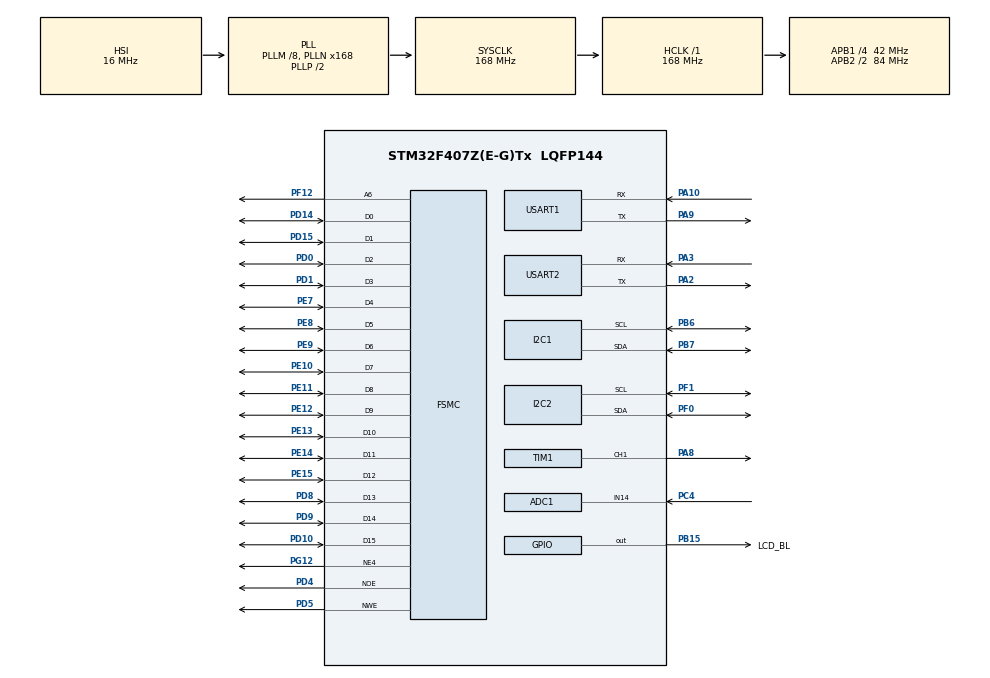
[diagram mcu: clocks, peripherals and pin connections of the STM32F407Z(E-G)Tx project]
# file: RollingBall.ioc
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ADC1.Channel-2\#ChannelRegularConversion=ADC_CHANNEL_14
ADC1.ContinuousConvMode=ENABLE
ADC1.NbrOfConversionFlag=1
ADC1.Rank-2\#ChannelRegularConversion=1
ADC1.SamplingTime-2\#ChannelRegularConversion=ADC_SAMPLETIME_3CYCLES
ADC1.master=1
I2C1.I2C_Mode=I2C_Fast
Mcu.Family=STM32F4
Mcu.Name=STM32F407Z(E-G)Tx
Mcu.Package=LQFP144
NVIC.ADC_IRQn=true\:0\:0\:false\:true\:true\:1\:true\:true
NVIC.PriorityGroup=NVIC_PRIORITYGROUP_4
NVIC.TIM2_IRQn=true\:15\:0\:false\:false\:true\:false\:true
NVIC.TimeBase=TIM2_IRQn
NVIC.TimeBaseIP=TIM2
NVIC.USART1_IRQn=true\:0\:0\:false\:true\:true\:2\:true\:true
NVIC.USART2_IRQn=true\:0\:0\:false\:true\:true\:3\:true\:true
PA10.Mode=Asynchronous
PA10.Signal=USART1_RX
PA13.Mode=JTAG_5_pins
PA13.Signal=SYS_JTMS-SWDIO
PA14.Mode=JTAG_5_pins
PA14.Signal=SYS_JTCK-SWCLK
PA15.Mode=JTAG_5_pins
PA15.Signal=SYS_JTDI
PA2.Mode=Asynchronous
PA2.Signal=USART2_TX
PA3.Mode=Asynchronous
PA3.Signal=USART2_RX
PA8.Signal=S_TIM1_CH1
PA9.Mode=Asynchronous
PA9.Signal=USART1_TX
PB15.GPIO_Label=LCD_BL
PB15.Signal=GPIO_Output
PB3.Mode=JTAG_5_pins
PB3.Signal=SYS_JTDO-SWO
PB4.Mode=JTAG_5_pins
PB4.Signal=SYS_JTRST
PB6.GPIO_Pu=GPIO_PULLUP
PB6.Mode=I2C
PB6.Signal=I2C1_SCL
PB7.GPIO_Pu=GPIO_PULLUP
PB7.Mode=I2C
PB7.Signal=I2C1_SDA
PC14-OSC32_IN.Mode=LSE-External-Oscillator
PC14-OSC32_IN.Signal=RCC_OSC32_IN
PC15-OSC32_OUT.Mode=LSE-External-Oscillator
PC15-OSC32_OUT.Signal=RCC_OSC32_OUT
PC4.Signal=ADCx_IN14
PD0.Signal=FSMC_D2_DA2
PD1.Signal=FSMC_D3_DA3
PD10.Signal=FSMC_D15_DA15
PD14.Signal=FSMC_D0_DA0
PD15.Signal=FSMC_D1_DA1
PD4.Signal=FSMC_NOE
PD5.Signal=FSMC_NWE
PD8.Signal=FSMC_D13_DA13
PD9.Signal=FSMC_D14_DA14
PE10.Signal=FSMC_D7_DA7
PE11.Signal=FSMC_D8_DA8
PE12.Signal=FSMC_D9_DA9
PE13.Signal=FSMC_D10_DA10
PE14.Signal=FSMC_D11_DA11
PE15.Signal=FSMC_D12_DA12
PE7.Signal=FSMC_D4_DA4
PE8.Signal=FSMC_D5_DA5
PE9.Signal=FSMC_D6_DA6
PF0.Mode=I2C
PF0.Signal=I2C2_SDA
PF1.Mode=I2C
PF1.Signal=I2C2_SCL
PF12.Signal=FSMC_A6
PG12.Mode=NorPsramChipSelect4_1
PG12.Signal=FSMC_NE4
PH0-OSC_IN.Mode=HSE-External-Oscillator
PH0-OSC_IN.Signal=RCC_OSC_IN
PH1-OSC_OUT.Mode=HSE-External-Oscillator
PH1-OSC_OUT.Signal=RCC_OSC_OUT
ProjectManager.HeapSize=0x200
ProjectManager.StackSize=0x400
ProjectManager.TargetToolchain=STM32CubeIDE
RCC.48MHZClocksFreq_Value=84000000
RCC.AHBFreq_Value=168000000
RCC.APB1CLKDivider=RCC_HCLK_DIV4
RCC.APB1Freq_Value=42000000
RCC.APB1TimFreq_Value=84000000
RCC.APB2CLKDivider=RCC_HCLK_DIV2
RCC.APB2Freq_Value=84000000
RCC.APB2TimFreq_Value=168000000
RCC.CortexFreq_Value=168000000
RCC.HCLKFreq_Value=168000000
RCC.HSE_VALUE=8000000
RCC.HSI_VALUE=16000000
RCC.PLLM=8
RCC.PLLN=168
RCC.SYSCLKFreq_VALUE=168000000
RCC.SYSCLKSource=RCC_SYSCLKSOURCE_PLLCLK
RCC.VCOOutputFreq_Value=336000000
SH.ADCx_IN14.0=ADC1_IN14,IN14
SH.FSMC_A6.0=FSMC_A6,A6_1
SH.FSMC_D0_DA0.0=FSMC_D0,16b-d1
SH.FSMC_D10_DA10.0=FSMC_D10,16b-d1
SH.FSMC_D11_DA11.0=FSMC_D11,16b-d1
SH.FSMC_D12_DA12.0=FSMC_D12,16b-d1
SH.FSMC_D13_DA13.0=FSMC_D13,16b-d1
SH.FSMC_D14_DA14.0=FSMC_D14,16b-d1
SH.FSMC_D15_DA15.0=FSMC_D15,16b-d1
SH.FSMC_D1_DA1.0=FSMC_D1,16b-d1
SH.FSMC_D2_DA2.0=FSMC_D2,16b-d1
SH.FSMC_D3_DA3.0=FSMC_D3,16b-d1
SH.FSMC_D4_DA4.0=FSMC_D4,16b-d1
SH.FSMC_D5_DA5.0=FSMC_D5,16b-d1
SH.FSMC_D6_DA6.0=FSMC_D6,16b-d1
SH.FSMC_D7_DA7.0=FSMC_D7,16b-d1
SH.FSMC_D8_DA8.0=FSMC_D8,16b-d1
SH.FSMC_D9_DA9.0=FSMC_D9,16b-d1
SH.FSMC_NOE.0=FSMC_NOE,Lcd1
SH.FSMC_NWE.0=FSMC_NWE,Lcd1
SH.S_TIM1_CH1.0=TIM1_CH1,PWM Generation1 CH1
TIM1.Channel-PWM\ Generation1\ CH1=TIM_CHANNEL_1
TIM1.Period=19999
TIM1.Prescaler=167
USART1.VirtualMode=VM_ASYNC
USART2.VirtualMode=VM_ASYNC
VP_SYS_VS_tim2.Mode=TIM2
VP_TIM1_VS_ClockSourceINT.Mode=Internal
board=custom

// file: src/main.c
/* USER CODE BEGIN Header */
/**
  ******************************************************************************
  * @file           : main.c
  * @brief          : Main program body
  ******************************************************************************
  * @attention
  *
  * <h2><center>&copy; Copyright (c) 2021 STMicroelectronics.
  * All rights reserved.</center></h2>
  *
  * This software component is licensed by ST under BSD 3-Clause license,
  * the "License"; You may not use this file except in compliance with the
  * License. You may obtain a copy of the License at:
  *                        opensource.org/licenses/BSD-3-Clause
  *
  ******************************************************************************
  */
/* USER CODE END Header */
#include "main.h"
#include "adc.h"
#include "i2c.h"
#include "tim.h"
#include "usart.h"
#include "gpio.h"
#include "fsmc.h"

/* USER CODE BEGIN Includes */
#include "RollingBall.h"
/* USER CODE END Includes */

void SystemClock_Config(void);
static void MX_NVIC_Init(void);

int main(void)
{

  /* MCU Configuration--------------------------------------------------------*/

  /* Reset of all peripherals, Initializes the Flash interface and the Systick. */
  HAL_Init();

  /* Configure the system clock */
  SystemClock_Config();

  /* Initialize all configured peripherals */
  MX_GPIO_Init();
  MX_TIM1_Init();
  MX_USART1_UART_Init();
  MX_USART2_UART_Init();
  MX_FSMC_Init();
  MX_I2C1_Init();
  MX_ADC1_Init();
  MX_I2C2_Init();

  /* Initialize interrupts */
  MX_NVIC_Init();
  /* USER CODE BEGIN 2 */
  rolling_ball_init();
  /* USER CODE END 2 */

  /* Infinite loop */
  while (1)
  {

    /* USER CODE BEGIN 3 */
    updateHandler();
  }
  /* USER CODE END 3 */
}

void SystemClock_Config(void)
{
  RCC_OscInitTypeDef RCC_OscInitStruct = {0};
  RCC_ClkInitTypeDef RCC_ClkInitStruct = {0};

  /** Configure the main internal regulator output voltage
  */
  __HAL_RCC_PWR_CLK_ENABLE();
  __HAL_PWR_VOLTAGESCALING_CONFIG(PWR_REGULATOR_VOLTAGE_SCALE1);
  /** Initializes the RCC Oscillators according to the specified parameters
  * in the RCC_OscInitTypeDef structure.
  */
  RCC_OscInitStruct.OscillatorType = RCC_OSCILLATORTYPE_HSI;
  RCC_OscInitStruct.HSIState = RCC_HSI_ON;
  RCC_OscInitStruct.HSICalibrationValue = RCC_HSICALIBRATION_DEFAULT;
  RCC_OscInitStruct.PLL.PLLState = RCC_PLL_ON;
  RCC_OscInitStruct.PLL.PLLSource = RCC_PLLSOURCE_HSI;
  RCC_OscInitStruct.PLL.PLLM = 8;
  RCC_OscInitStruct.PLL.PLLN = 168;
  RCC_OscInitStruct.PLL.PLLP = RCC_PLLP_DIV2;
  RCC_OscInitStruct.PLL.PLLQ = 4;
  if (HAL_RCC_OscConfig(&RCC_OscInitStruct) != HAL_OK)
  {
    Error_Handler();
  }
  /** Initializes the CPU, AHB and APB buses clocks
  */
  RCC_ClkInitStruct.ClockType = RCC_CLOCKTYPE_HCLK|RCC_CLOCKTYPE_SYSCLK
                              |RCC_CLOCKTYPE_PCLK1|RCC_CLOCKTYPE_PCLK2;
  RCC_ClkInitStruct.SYSCLKSource = RCC_SYSCLKSOURCE_PLLCLK;
  RCC_ClkInitStruct.AHBCLKDivider = RCC_SYSCLK_DIV1;
  RCC_ClkInitStruct.APB1CLKDivider = RCC_HCLK_DIV4;
  RCC_ClkInitStruct.APB2CLKDivider = RCC_HCLK_DIV2;

  if (HAL_RCC_ClockConfig(&RCC_ClkInitStruct, FLASH_LATENCY_5) != HAL_OK)
  {
    Error_Handler();
  }
}

/**
  * @brief NVIC Configuration.
  * @retval None
  */
static void MX_NVIC_Init(void)
{
  /* ADC_IRQn interrupt configuration */
  HAL_NVIC_SetPriority(ADC_IRQn, 0, 0);
  HAL_NVIC_EnableIRQ(ADC_IRQn);
  /* USART1_IRQn interrupt configuration */
  HAL_NVIC_SetPriority(USART1_IRQn, 0, 0);
  HAL_NVIC_EnableIRQ(USART1_IRQn);
  /* USART2_IRQn interrupt configuration */
  HAL_NVIC_SetPriority(USART2_IRQn, 0, 0);
  HAL_NVIC_EnableIRQ(USART2_IRQn);
}

void HAL_TIM_PeriodElapsedCallback(TIM_HandleTypeDef *htim)
{
  if (htim->Instance == TIM2) {
    HAL_IncTick();
  }
}

void Error_Handler(void)
{
  __disable_irq();
  while (1)
  {
  }
}

/************************ (C) COPYRIGHT STMicroelectronics *****END OF FILE****/
